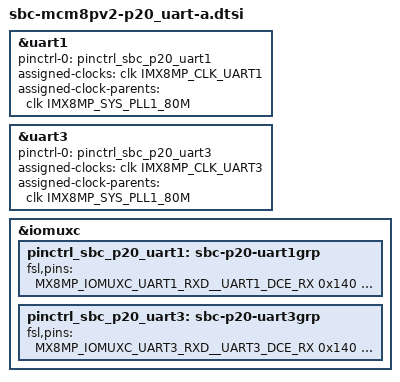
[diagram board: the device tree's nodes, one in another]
// SPDX-License-Identifier: (GPL-2.0+ OR MIT)
/* Copyright 2026 CompuLab Ltd. */

/* P20 exposes two independent TX/RX pairs, without RTS/CTS. */
&uart1 {
	pinctrl-names = "default";
	pinctrl-0 = <&pinctrl_sbc_p20_uart1>;
	assigned-clocks = <&clk IMX8MP_CLK_UART1>;
	assigned-clock-parents = <&clk IMX8MP_SYS_PLL1_80M>;
	status = "okay";
};

&uart3 {
	pinctrl-names = "default";
	pinctrl-0 = <&pinctrl_sbc_p20_uart3>;
	assigned-clocks = <&clk IMX8MP_CLK_UART3>;
	assigned-clock-parents = <&clk IMX8MP_SYS_PLL1_80M>;
	status = "okay";
};

&iomuxc {
	pinctrl_sbc_p20_uart1: sbc-p20-uart1grp {
		fsl,pins = <
			MX8MP_IOMUXC_UART1_RXD__UART1_DCE_RX	0x140 /* P20.2 */
			MX8MP_IOMUXC_UART1_TXD__UART1_DCE_TX	0x140 /* P20.4 */
		>;
	};
};

&iomuxc {
	pinctrl_sbc_p20_uart3: sbc-p20-uart3grp {
		fsl,pins = <
			MX8MP_IOMUXC_UART3_RXD__UART3_DCE_RX	0x140 /* P20.6 */
			MX8MP_IOMUXC_UART3_TXD__UART3_DCE_TX	0x140 /* P20.3 */
		>;
	};
};
